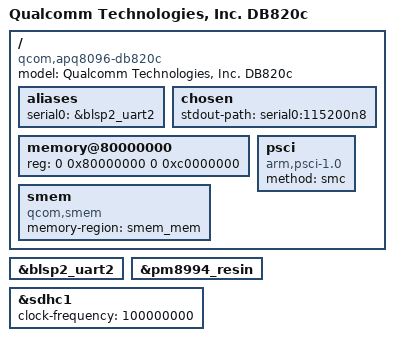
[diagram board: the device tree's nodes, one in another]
// SPDX-License-Identifier: GPL-2.0+
/*
 * Qualcomm APQ8096 based Dragonboard 820C board device tree source
 *
 * (C) Copyright 2017 Jorge Ramirez-Ortiz <jorge.ramirez-ortiz@linaro.org>
 */

/dts-v1/;

#include "msm8996.dtsi"
#include "pm8994.dtsi"

/ {
	model = "Qualcomm Technologies, Inc. DB820c";
	compatible = "qcom,apq8096-db820c", "qcom,apq8096";
	#address-cells = <2>;
	#size-cells = <2>;

	aliases {
		serial0 = &blsp2_uart2;
	};

	chosen {
		stdout-path = "serial0:115200n8";
	};

	memory@80000000 {
		device_type = "memory";
		reg = <0 0x80000000 0 0xc0000000>;
	};

	psci {
		compatible = "arm,psci-1.0";
		method = "smc";
	};

	smem {
		compatible = "qcom,smem";
		memory-region = <&smem_mem>;
	};
};

&blsp2_uart2 {
	status = "okay";
};

&pm8994_resin {
	status = "okay";
};

&sdhc1 {
	status = "okay";
	clock-frequency = <100000000>;
};
